# Espressif register map
File version: 1.0
CPU: Xtensa LX6 1, little endian, no MPU, FPU, 3 interrupt priority bits
Registers are 32-bit, access not given, reset 0x0 unless marked. A register's access mark holds for its fields unless they carry their own. Offsets are from the block's base; [hi:lo] are bit positions; {n}, {i} and the like mark numbered series.

## PCNT
Base 0x3FF57000
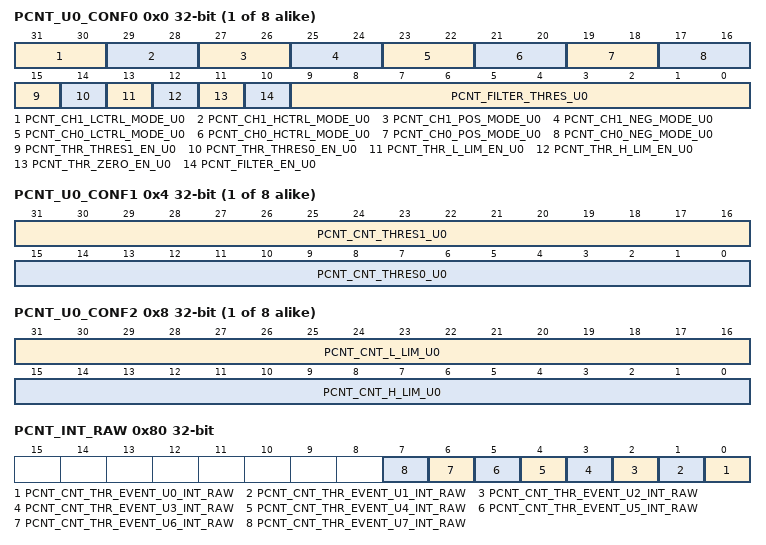
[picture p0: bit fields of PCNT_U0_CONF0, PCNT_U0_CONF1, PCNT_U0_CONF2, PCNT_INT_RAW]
{0x0+0xC*i} PCNT_U{i}_CONF0 (i=0..7)
  [31:30] PCNT_CH1_LCTRL_MODE_U{i}, [29:28] PCNT_CH1_HCTRL_MODE_U{i}, [27:26] PCNT_CH1_POS_MODE_U{i}, [25:24] PCNT_CH1_NEG_MODE_U{i}, [23:22] PCNT_CH0_LCTRL_MODE_U{i}, [21:20] PCNT_CH0_HCTRL_MODE_U{i}, [19:18] PCNT_CH0_POS_MODE_U{i}, [17:16] PCNT_CH0_NEG_MODE_U{i}, [15] PCNT_THR_THRES1_EN_U{i}, [14] PCNT_THR_THRES0_EN_U{i}, [13] PCNT_THR_L_LIM_EN_U{i}, [12] PCNT_THR_H_LIM_EN_U{i}, [11] PCNT_THR_ZERO_EN_U{i}, [10] PCNT_FILTER_EN_U{i}, [9:0] PCNT_FILTER_THRES_U{i}
{0x4+0xC*i} PCNT_U{i}_CONF1 (i=0..7)
  [31:16] PCNT_CNT_THRES1_U{i}, [15:0] PCNT_CNT_THRES0_U{i}
{0x8+0xC*i} PCNT_U{i}_CONF2 (i=0..7)
  [31:16] PCNT_CNT_L_LIM_U{i}, [15:0] PCNT_CNT_H_LIM_U{i}
{0x60+4i} PCNT_U{i}_CNT (i=0..7)
  [15:0] PCNT_PLUS_CNT_U{i}
0x80 PCNT_INT_RAW
  [n] PCNT_CNT_THR_EVENT_U{n}_INT_RAW (n=0..7)
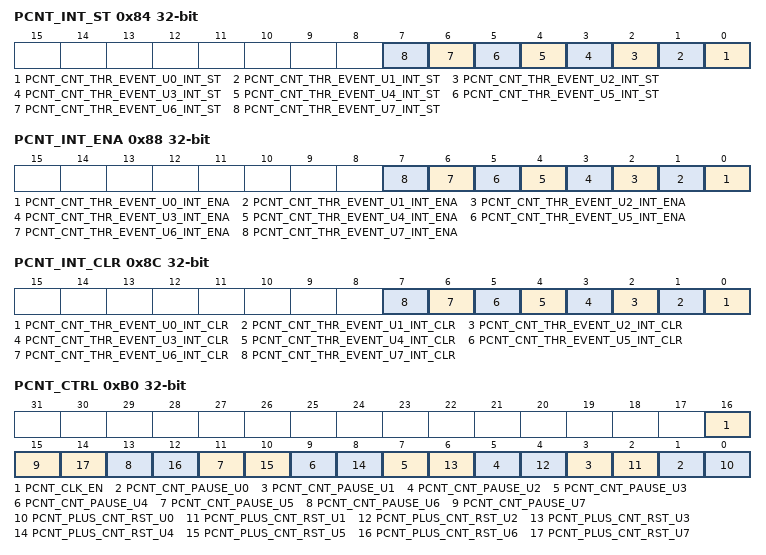
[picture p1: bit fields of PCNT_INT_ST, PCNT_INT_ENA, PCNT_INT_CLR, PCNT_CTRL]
0x84 PCNT_INT_ST
  [n] PCNT_CNT_THR_EVENT_U{n}_INT_ST (n=0..7)
0x88 PCNT_INT_ENA
  [n] PCNT_CNT_THR_EVENT_U{n}_INT_ENA (n=0..7)
0x8C PCNT_INT_CLR
  [n] PCNT_CNT_THR_EVENT_U{n}_INT_CLR (n=0..7)
{0x90+4i} PCNT_U{i}_STATUS (i=0..7)
  [31:0] PCNT_CORE_STATUS_U{i}
0xB0 PCNT_CTRL
  [16] PCNT_CLK_EN, [2n+1] PCNT_CNT_PAUSE_U{n} (n=0..7), [2n] PCNT_PLUS_CNT_RST_U{n} (n=0..7)
0xFC PCNT_DATE

## RMT
Base 0x3FF56000
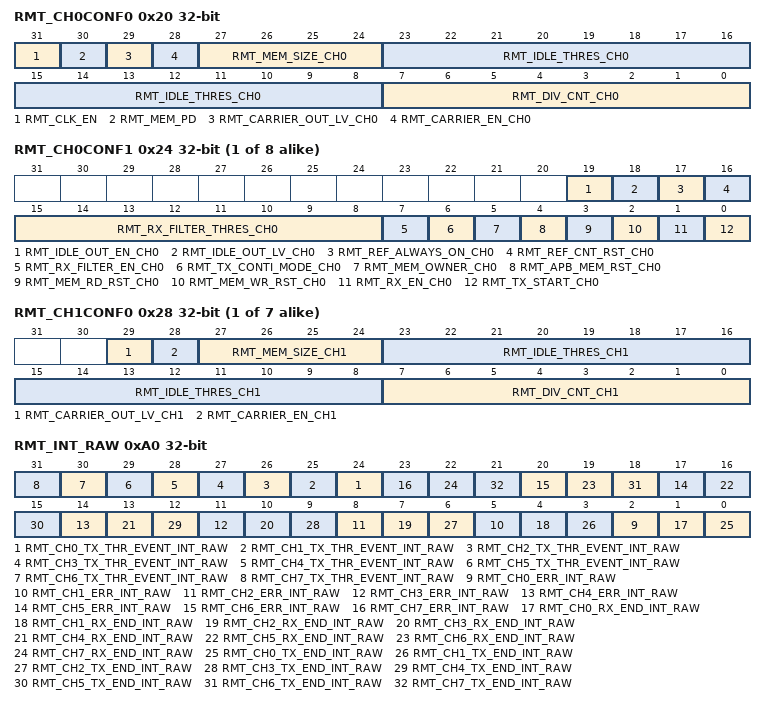
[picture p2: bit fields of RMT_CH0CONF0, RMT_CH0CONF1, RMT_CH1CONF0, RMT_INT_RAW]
0x20 RMT_CH0CONF0
  [31] RMT_CLK_EN, [30] RMT_MEM_PD, [29] RMT_CARRIER_OUT_LV_CH0, [28] RMT_CARRIER_EN_CH0, [27:24] RMT_MEM_SIZE_CH0, [23:8] RMT_IDLE_THRES_CH0, [7:0] RMT_DIV_CNT_CH0
{0x24+8i} RMT_CH{i}CONF1 (i=0..7)
  [19] RMT_IDLE_OUT_EN_CH{i}, [18] RMT_IDLE_OUT_LV_CH{i}, [17] RMT_REF_ALWAYS_ON_CH{i}, [16] RMT_REF_CNT_RST_CH{i}, [15:8] RMT_RX_FILTER_THRES_CH{i}, [7] RMT_RX_FILTER_EN_CH{i}, [6] RMT_TX_CONTI_MODE_CH{i}, [5] RMT_MEM_OWNER_CH{i}, [4] RMT_APB_MEM_RST_CH{i}, [3] RMT_MEM_RD_RST_CH{i}, [2] RMT_MEM_WR_RST_CH{i}, [1] RMT_RX_EN_CH{i}, [0] RMT_TX_START_CH{i}
{0x20+8i} RMT_CH{i}CONF0 (i=1..7)
  [29] RMT_CARRIER_OUT_LV_CH{i}, [28] RMT_CARRIER_EN_CH{i}, [27:24] RMT_MEM_SIZE_CH{i}, [23:8] RMT_IDLE_THRES_CH{i}, [7:0] RMT_DIV_CNT_CH{i}
{0x60+4i} RMT_CH{i}STATUS (i=0..7)
  [31] RMT_APB_MEM_RD_ERR_CH{i}, [30] RMT_APB_MEM_WR_ERR_CH{i}, [29] RMT_MEM_EMPTY_CH{i}, [28] RMT_MEM_FULL_CH{i}, [27] RMT_MEM_OWNER_ERR_CH{i}, [26:24] RMT_STATE_CH{i}, [21:12] RMT_MEM_RADDR_EX_CH{i}, [31:0] RMT_STATUS_CH{i}, [9:0] RMT_MEM_WADDR_EX_CH{i}
{0x80+4i} RMT_CH{i}ADDR (i=0..7)
  [31:0] RMT_APB_MEM_ADDR_CH{i}
0xA0 RMT_INT_RAW
  [n+24] RMT_CH{n}_TX_THR_EVENT_INT_RAW (n=0..7), [3n+2] RMT_CH{n}_ERR_INT_RAW (n=0..7), [3n+1] RMT_CH{n}_RX_END_INT_RAW (n=0..7), [3n] RMT_CH{n}_TX_END_INT_RAW (n=0..7)
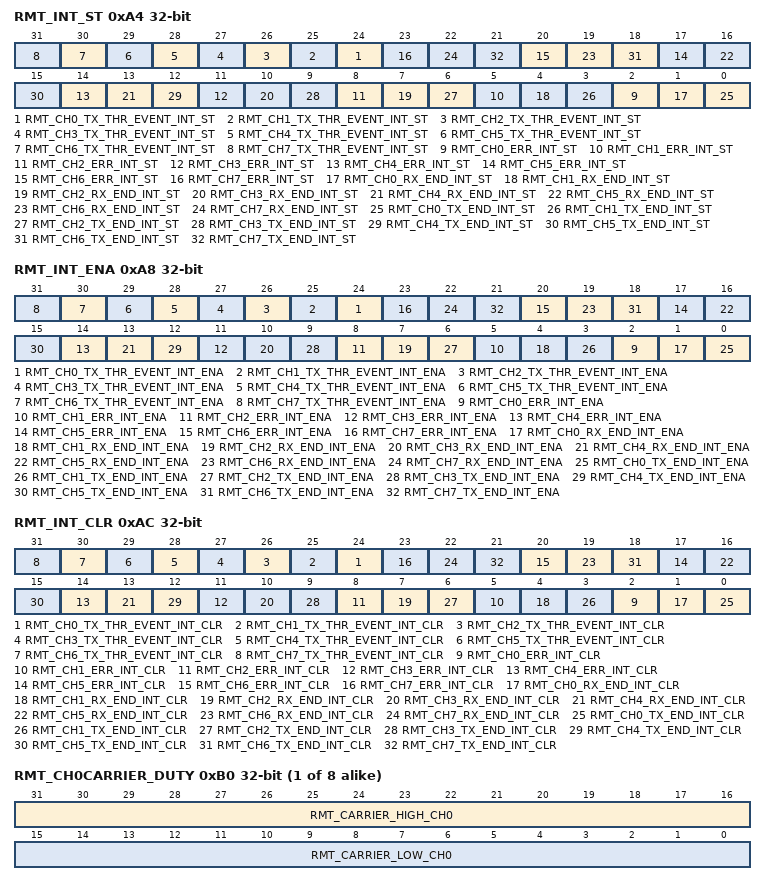
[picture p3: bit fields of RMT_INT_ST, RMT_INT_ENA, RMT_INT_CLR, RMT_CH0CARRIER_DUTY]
0xA4 RMT_INT_ST
  [n+24] RMT_CH{n}_TX_THR_EVENT_INT_ST (n=0..7), [3n+2] RMT_CH{n}_ERR_INT_ST (n=0..7), [3n+1] RMT_CH{n}_RX_END_INT_ST (n=0..7), [3n] RMT_CH{n}_TX_END_INT_ST (n=0..7)
0xA8 RMT_INT_ENA
  [n+24] RMT_CH{n}_TX_THR_EVENT_INT_ENA (n=0..7), [3n+2] RMT_CH{n}_ERR_INT_ENA (n=0..7), [3n+1] RMT_CH{n}_RX_END_INT_ENA (n=0..7), [3n] RMT_CH{n}_TX_END_INT_ENA (n=0..7)
0xAC RMT_INT_CLR
  [n+24] RMT_CH{n}_TX_THR_EVENT_INT_CLR (n=0..7), [3n+2] RMT_CH{n}_ERR_INT_CLR (n=0..7), [3n+1] RMT_CH{n}_RX_END_INT_CLR (n=0..7), [3n] RMT_CH{n}_TX_END_INT_CLR (n=0..7)
{0xB0+4i} RMT_CH{i}CARRIER_DUTY (i=0..7)
  [31:16] RMT_CARRIER_HIGH_CH{i}, [15:0] RMT_CARRIER_LOW_CH{i}
{0xD0+4i} RMT_CH{i}_TX_LIM (i=0..7)
  [8:0] RMT_TX_LIM_CH{i}
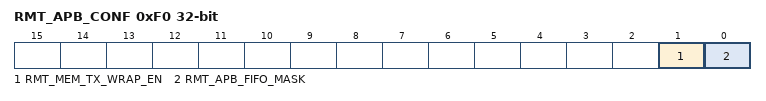
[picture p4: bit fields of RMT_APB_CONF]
0xF0 RMT_APB_CONF
  [1] RMT_MEM_TX_WRAP_EN, [0] RMT_APB_FIFO_MASK
0xFC RMT_DATE

## GPIO
Base 0x3FF44000
0x00 GPIO_BT_SELECT
  [31:0] GPIO_BT_SEL
0x04 GPIO_OUT
  [31:0] GPIO_OUT_DATA
0x08 GPIO_OUT_W1TS
  [31:0] GPIO_OUT_DATA_W1TS
0x0C GPIO_OUT_W1TC
  [31:0] GPIO_OUT_DATA_W1TC
0x10 GPIO_OUT1
  [7:0] GPIO_OUT1_DATA
0x14 GPIO_OUT1_W1TS
  [7:0] GPIO_OUT1_DATA_W1TS
0x18 GPIO_OUT1_W1TC
  [7:0] GPIO_OUT1_DATA_W1TC
0x1C GPIO_SDIO_SELECT
  [7:0] GPIO_SDIO_SEL
0x20 GPIO_ENABLE
  [31:0] GPIO_ENABLE_DATA
0x24 GPIO_ENABLE_W1TS
  [31:0] GPIO_ENABLE_DATA_W1TS
0x28 GPIO_ENABLE_W1TC
  [31:0] GPIO_ENABLE_DATA_W1TC
0x2C GPIO_ENABLE1
  [7:0] GPIO_ENABLE1_DATA
0x30 GPIO_ENABLE1_W1TS
  [7:0] GPIO_ENABLE1_DATA_W1TS
0x34 GPIO_ENABLE1_W1TC
  [7:0] GPIO_ENABLE1_DATA_W1TC
0x38 GPIO_STRAP
  [15:0] GPIO_STRAPPING
0x3C GPIO_IN
  [31:0] GPIO_IN_DATA
0x40 GPIO_IN1
  [7:0] GPIO_IN1_DATA
0x44 GPIO_STATUS
  [31:0] GPIO_STATUS_INT
0x48 GPIO_STATUS_W1TS
  [31:0] GPIO_STATUS_INT_W1TS
0x4C GPIO_STATUS_W1TC
  [31:0] GPIO_STATUS_INT_W1TC
0x50 GPIO_STATUS1
  [7:0] GPIO_STATUS1_INT
0x54 GPIO_STATUS1_W1TS
  [7:0] GPIO_STATUS1_INT_W1TS
0x58 GPIO_STATUS1_W1TC
  [7:0] GPIO_STATUS1_INT_W1TC
0x60 GPIO_ACPU_INT
  [31:0] GPIO_APPCPU_INT
0x64 GPIO_ACPU_NMI_INT
  [31:0] GPIO_APPCPU_NMI_INT
0x68 GPIO_PCPU_INT
  [31:0] GPIO_PROCPU_INT
0x6C GPIO_PCPU_NMI_INT
  [31:0] GPIO_PROCPU_NMI_INT
0x70 GPIO_CPUSDIO_INT
  [31:0] GPIO_SDIO_INT
0x74 GPIO_ACPU_INT1
  [7:0] GPIO_APPCPU_INT_H
0x78 GPIO_ACPU_NMI_INT1
  [7:0] GPIO_APPCPU_NMI_INT_H
0x7C GPIO_PCPU_INT1
  [7:0] GPIO_PROCPU_INT_H
0x80 GPIO_PCPU_NMI_INT1
  [7:0] GPIO_PROCPU_NMI_INT_H
0x84 GPIO_CPUSDIO_INT1
  [7:0] GPIO_SDIO_INT_H
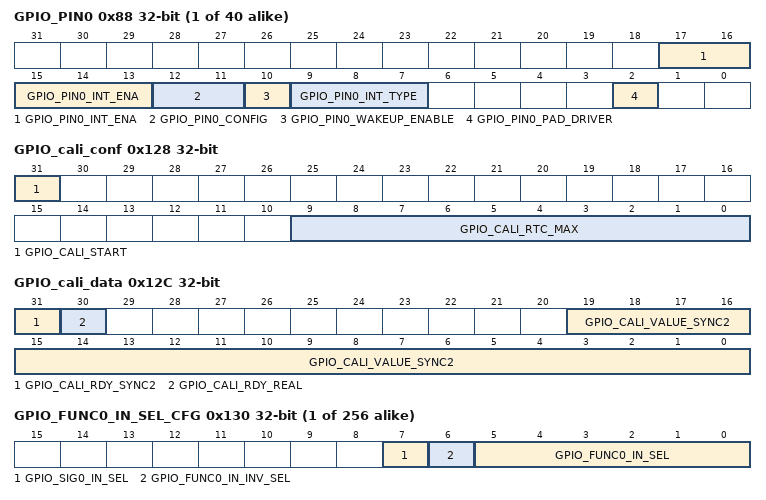
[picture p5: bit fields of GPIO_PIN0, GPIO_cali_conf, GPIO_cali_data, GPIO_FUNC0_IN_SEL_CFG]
{0x88+4i} GPIO_PIN{i} (i=0..39)
  [17:13] GPIO_PIN{i}_INT_ENA, [12:11] GPIO_PIN{i}_CONFIG, [10] GPIO_PIN{i}_WAKEUP_ENABLE, [9:7] GPIO_PIN{i}_INT_TYPE, [2] GPIO_PIN{i}_PAD_DRIVER
0x128 GPIO_cali_conf
  [31] GPIO_CALI_START, [9:0] GPIO_CALI_RTC_MAX
0x12C GPIO_cali_data
  [31] GPIO_CALI_RDY_SYNC2, [30] GPIO_CALI_RDY_REAL, [19:0] GPIO_CALI_VALUE_SYNC2
{0x130+4i} GPIO_FUNC{i}_IN_SEL_CFG (i=0..255)
  [7] GPIO_SIG{i}_IN_SEL, [6] GPIO_FUNC{i}_IN_INV_SEL, [5:0] GPIO_FUNC{i}_IN_SEL
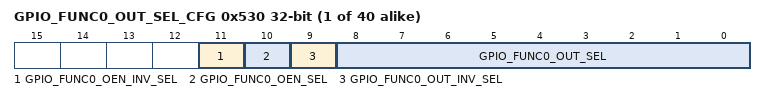
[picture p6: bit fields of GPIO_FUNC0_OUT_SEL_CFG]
{0x530+4i} GPIO_FUNC{i}_OUT_SEL_CFG (i=0..39)
  [11] GPIO_FUNC{i}_OEN_INV_SEL, [10] GPIO_FUNC{i}_OEN_SEL, [9] GPIO_FUNC{i}_OUT_INV_SEL, [8:0] GPIO_FUNC{i}_OUT_SEL
